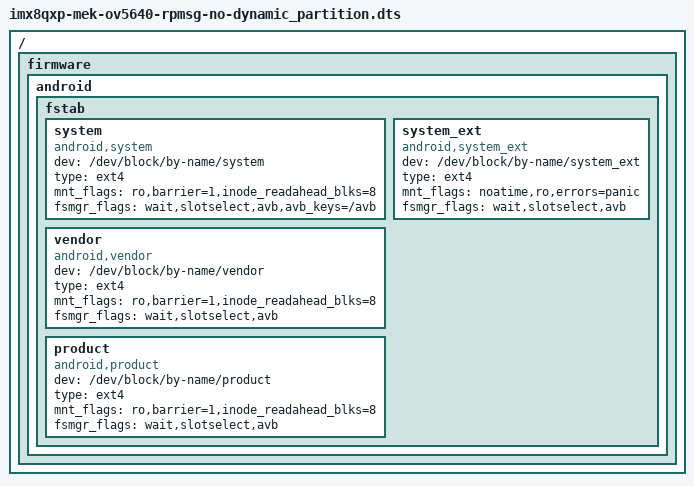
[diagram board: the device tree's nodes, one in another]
/*
 * Copyright 2019 NXP
 *
 * This program is free software; you can redistribute it and/or
 * modify it under the terms of the GNU General Public License
 * as published by the Free Software Foundation; either version 2
 * of the License, or (at your option) any later version.
 *
 * This program is distributed in the hope that it will be useful,
 * but WITHOUT ANY WARRANTY; without even the implied warranty of
 * MERCHANTABILITY or FITNESS FOR A PARTICULAR PURPOSE.  See the
 * GNU General Public License for more details.
 */

#include "imx8qxp-mek-ov5640-rpmsg.dts"

/ {
	firmware {
		android {
			fstab {
				system {
					compatible = "android,system";
					dev = "/dev/block/by-name/system";
					type = "ext4";
					mnt_flags = "ro,barrier=1,inode_readahead_blks=8";
					fsmgr_flags = "wait,slotselect,avb,avb_keys=/avb";
				};
				system_ext {
					compatible = "android,system_ext";
					dev = "/dev/block/by-name/system_ext";
					type = "ext4";
					mnt_flags = "noatime,ro,errors=panic";
					fsmgr_flags = "wait,slotselect,avb";
				};
				vendor {
					compatible = "android,vendor";
					dev = "/dev/block/by-name/vendor";
					type = "ext4";
					mnt_flags = "ro,barrier=1,inode_readahead_blks=8";
					fsmgr_flags = "wait,slotselect,avb";
				};
				product {
					compatible = "android,product";
					dev = "/dev/block/by-name/product";
					type = "ext4";
					mnt_flags = "ro,barrier=1,inode_readahead_blks=8";
					fsmgr_flags = "wait,slotselect,avb";
				};
			};
		};
	};
};
